# STM32G0B1 register map
File version: 1.8
CPU: CM0 r0p1, little endian, MPU, no FPU, 4 interrupt priority bits
Registers are 32-bit, read-write, reset 0x0 unless marked. A register's access mark holds for its fields unless they carry their own. Offsets are from the block's base; [hi:lo] are bit positions.

## DBG — Debug support
Base 0x40015800
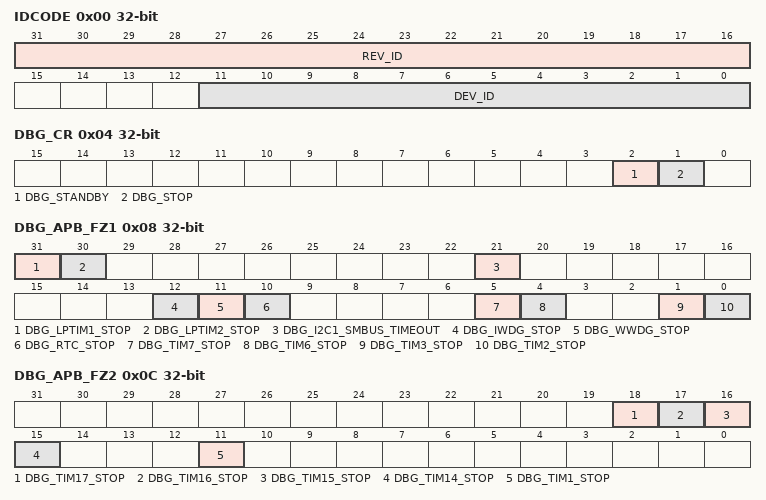
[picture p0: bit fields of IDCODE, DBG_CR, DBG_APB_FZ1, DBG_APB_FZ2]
0x00 IDCODE ro — MCU Device ID Code Register
  [31:16] REV_ID — Revision Identifier
  [11:0] DEV_ID — Device Identifier
0x04 DBG_CR — DBG configuration register
  [2] DBG_STANDBY — Debug Standby and Shutdown modes Debug options in Standby or Shutdown mode.
    0=Digital part powered. From software point of view, exiting Standby and Shutdown modes is identical as fetching reset vector (except for status bits indicating that the MCU exits Standby); 1=Digital part powered and FCLK and HCLK running, derived from the internal RC oscillator remaining active. The MCU generates a system reset so that exiting Standby and Shutdown has the same effect as starting from reset.
  [1] DBG_STOP — Debug Stop mode Debug options in Stop mode. Upon Stop mode exit, the software must re-establish the desired clock configuration.
    0=All clocks disabled, including FCLK and HCLK. Upon Stop mode exit, the CPU is clocked by the HSI internal RC oscillator.; 1=FCLK and HCLK running, derived from the internal RC oscillator remaining active. If Systick is enabled, it may generate periodic interrupt and wake up events.
0x08 DBG_APB_FZ1 — DBG APB freeze register 1
  [31] DBG_LPTIM1_STOP — Clocking of LPTIMER1 counter when the core is halted This bit enables/disables the clock to the counter of LPTIMER1 when the core is halted:
    0=Enable; 1=Disable
  [30] DBG_LPTIM2_STOP — Clocking of LPTIMER2 counter when the core is halted This bit enables/disables the clock to the counter of LPTIMER2 when the core is halted:
    0=Enable; 1=Disable
  [21] DBG_I2C1_SMBUS_TIMEOUT — SMBUS timeout when core is halted
    0=Same behavior as in normal mode; 1=The SMBUS timeout is frozen
  [12] DBG_IWDG_STOP — Clocking of IWDG counter when the core is halted This bit enables/disables the clock to the counter of IWDG when the core is halted:
    0=Enable; 1=Disable
  [11] DBG_WWDG_STOP — Clocking of WWDG counter when the core is halted This bit enables/disables the clock to the counter of WWDG when the core is halted:
    0=Enable; 1=Disable
  [10] DBG_RTC_STOP — Clocking of RTC counter when the core is halted This bit enables/disables the clock to the counter of RTC when the core is halted:
    0=Enable; 1=Disable
  [5] DBG_TIM7_STOP — Clocking of TIM7 counter when the core is halted. This bit enables/disables the clock to the counter of ITIM7 when the core is halted:
    0=Enable; 1=Disable
  [4] DBG_TIM6_STOP — Clocking of TIM6 counter when the core is halted This bit enables/disables the clock to the counter of TIM6 when the core is halted:
    0=Enable; 1=Disable
  [1] DBG_TIM3_STOP — Clocking of TIM3 counter when the core is halted This bit enables/disables the clock to the counter of TIM3 when the core is halted:
    0=Enable; 1=Disable
  [0] DBG_TIM2_STOP — Clocking of TIM2 counter when the core is halted This bit enables/disables the clock to the counter of TIM2 when the core is halted:
    0=Enable; 1=Disable
0x0C DBG_APB_FZ2 — DBG APB freeze register 2
  [all] fields
    0=Enable; 1=Disable
  [18] DBG_TIM17_STOP — Clocking of TIM17 counter when the core is halted This bit enables/disables the clock to the counter of TIM17 when the core is halted:
  [17] DBG_TIM16_STOP — Clocking of TIM16 counter when the core is halted This bit enables/disables the clock to the counter of TIM16 when the core is halted:
  [16] DBG_TIM15_STOP — Clocking of TIM15 counter when the core is halted This bit enables/disables the clock to the counter of TIM15 when the core is halted: Only available on STM32G071xx and STM32G081xx, reserved on STM32G031xx and STM32G041xx.
  [15] DBG_TIM14_STOP — Clocking of TIM14 counter when the core is halted This bit enables/disables the clock to the counter of TIM14 when the core is halted:
  [11] DBG_TIM1_STOP — Clocking of TIM1 counter when the core is halted This bit enables/disables the clock to the counter of TIM1 when the core is halted:
